# DA1469x register map
Vendor: Dialog; Series: DA1469x; File version: 1.2
CPU: CM33 r1p0, little endian, no MPU, FPU, 3 interrupt priority bits
Registers are 32-bit, read-write, reset 0x0 unless marked. A register's access mark holds for its fields unless they carry their own. Offsets are from the block's base; [hi:lo] are bit positions; 'fields as' and 'values as' point back to an identical list.

## CRG_COM — CRG_COM registers
Base 0x50020900
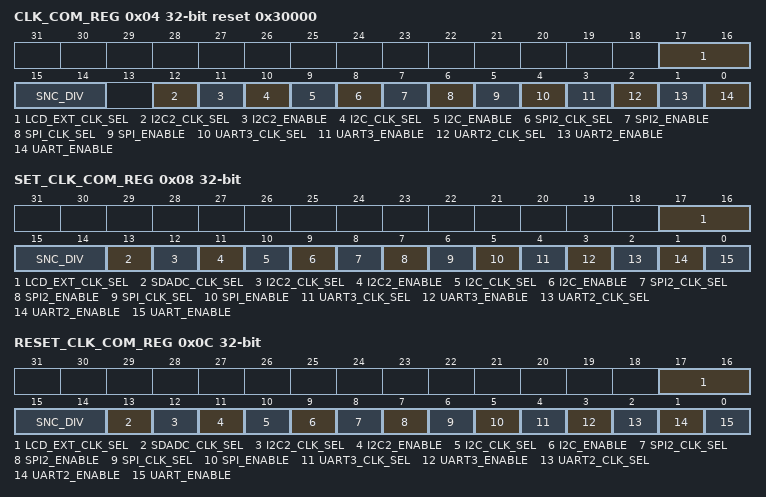
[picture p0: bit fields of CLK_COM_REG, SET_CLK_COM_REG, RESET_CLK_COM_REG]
0x04 CLK_COM_REG reset 0x30000 — Peripheral divider register
  [17:16] LCD_EXT_CLK_SEL — Select LCD external clock speed. 0x0: 1 Hz 0x1: 62.5 Hz 0x2: 125 Hz 0x3: off
  [15:14] SNC_DIV — Division factor for SNC, w.r.t. pclk setting 0x0 = divide by 1 0x1 = divide by 2 0x2 = divide by 4 0x3 = divide by 8
  [12] I2C2_CLK_SEL — Selects the clock source 1 = DIV1 clock 0 = DIVN clock
  [11] I2C2_ENABLE — Enables the clock
  [10] I2C_CLK_SEL — Selects the clock source 1 = DIV1 clock 0 = DIVN clock
  [9] I2C_ENABLE — Enables the clock
  [8] SPI2_CLK_SEL — Selects the clock source 1 = DIV1 clock 0 = DIVN clock
  [7] SPI2_ENABLE — Enables the clock
  [6] SPI_CLK_SEL — Selects the clock source 1 = DIV1 clock 0 = DIVN clock
  [5] SPI_ENABLE — Enables the clock
  [4] UART3_CLK_SEL — Selects the clock source 1 = DIV1 clock 0 = DIVN clock
  [3] UART3_ENABLE — Enables the clock
  [2] UART2_CLK_SEL — Selects the clock source 1 = DIV1 clock 0 = DIVN clock
  [1] UART2_ENABLE — Enables the clock
  [0] UART_ENABLE — Enables the clock
0x08 SET_CLK_COM_REG — Peripheral divider register SET register. Reads back 0x0000
  [17:16] LCD_EXT_CLK_SEL rw-once — Select LCD external clock speed. 0x0: 1 Hz 0x1: 62.5 Hz 0x2: 125 Hz 0x3: off
  [15:14] SNC_DIV rw-once — Division factor for SNC, w.r.t. pclk setting 0x0 = divide by 1 0x1 = divide by 2 0x2 = divide by 4 0x3 = divide by 8
  [13] SDADC_CLK_SEL rw-once — Selects the clock source 1 = DIV1 clock 0 = DIVN clock
  [12] I2C2_CLK_SEL rw-once — Selects the clock source 1 = DIV1 clock 0 = DIVN clock
  [11] I2C2_ENABLE rw-once — Enables the clock
  [10] I2C_CLK_SEL rw-once — Selects the clock source 1 = DIV1 clock 0 = DIVN clock
  [9] I2C_ENABLE rw-once — Enables the clock
  [8] SPI2_CLK_SEL rw-once — Selects the clock source 1 = DIV1 clock 0 = DIVN clock
  [7] SPI2_ENABLE rw-once — Enables the clock
  [6] SPI_CLK_SEL rw-once — Selects the clock source 1 = DIV1 clock 0 = DIVN clock
  [5] SPI_ENABLE rw-once — Enables the clock
  [4] UART3_CLK_SEL rw-once — Selects the clock source 1 = DIV1 clock 0 = DIVN clock
  [3] UART3_ENABLE rw-once — Enables the clock
  [2] UART2_CLK_SEL rw-once — Selects the clock source 1 = DIV1 clock 0 = DIVN clock
  [1] UART2_ENABLE rw-once — Enables the clock
  [0] UART_ENABLE rw-once — Enables the clock
0x0C RESET_CLK_COM_REG — Peripheral divider register RESET register. Reads back 0x0000
  [17:16] LCD_EXT_CLK_SEL — Select LCD external clock speed. 0x0: 1 Hz 0x1: 62.5 Hz 0x2: 125 Hz 0x3: off
  [15:14] SNC_DIV — Division factor for SNC, w.r.t. pclk setting 0x0 = divide by 1 0x1 = divide by 2 0x2 = divide by 4 0x3 = divide by 8
  [13] SDADC_CLK_SEL — Selects the clock source 1 = DIV1 clock 0 = DIVN clock
  [12] I2C2_CLK_SEL — Selects the clock source 1 = DIV1 clock 0 = DIVN clock
  [11] I2C2_ENABLE — Enables the clock
  [10] I2C_CLK_SEL — Selects the clock source 1 = DIV1 clock 0 = DIVN clock
  [9] I2C_ENABLE — Enables the clock
  [8] SPI2_CLK_SEL — Selects the clock source 1 = DIV1 clock 0 = DIVN clock
  [7] SPI2_ENABLE — Enables the clock
  [6] SPI_CLK_SEL — Selects the clock source 1 = DIV1 clock 0 = DIVN clock
  [5] SPI_ENABLE — Enables the clock
  [4] UART3_CLK_SEL — Selects the clock source 1 = DIV1 clock 0 = DIVN clock
  [3] UART3_ENABLE — Enables the clock
  [2] UART2_CLK_SEL — Selects the clock source 1 = DIV1 clock 0 = DIVN clock
  [1] UART2_ENABLE — Enables the clock
  [0] UART_ENABLE — Enables the clock

## CRG_PER — CRG_PER registers
Base 0x50030C00
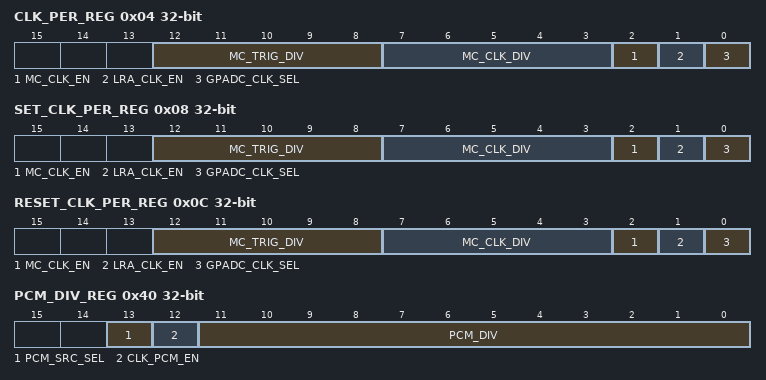
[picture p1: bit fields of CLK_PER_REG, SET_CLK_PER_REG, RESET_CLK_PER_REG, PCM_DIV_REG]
0x04 CLK_PER_REG — Peripheral divider register
  [12:8] MC_TRIG_DIV — Trigger divider for the motor controller 0x0: divide LP_CLK by 1 0x1: divide LP_CLK by 2 ... 0x1F: divide LP_CLK by 32
  [7:3] MC_CLK_DIV — Clock divider for the motor controller slot. The slots are clocked on (a PCLK synchronized version of) the LP clock, and can be further divided by this divider: 0x0: divide LP clock by 1 0x1: divide LP clock by 2 ... 0x1F: divide LP clock by 32
  [2] MC_CLK_EN — Enables the clock
  [1] LRA_CLK_EN — Enables the clock
  [0] GPADC_CLK_SEL — Selects the clock source 1 = DIV1 clock 0 = DIVN clock/ 2
0x08 SET_CLK_PER_REG — Peripheral divider register SET register, reads 0x0000
  [12:8] MC_TRIG_DIV rw-once — Trigger divider for the motor controller 0x0: divide LP_CLK by 1 0x1: divide LP_CLK by 2 ... 0x1F: divide LP_CLK by 32
  [7:3] MC_CLK_DIV rw-once — Clock divider for the motor controller slot. The slots are clocked on (a PCLK synchronized version of) the LP clock, and can be further divided by this divider: 0x0: divide LP clock by 1 0x1: divide LP clock by 2 ... 0x1F: divide LP clock by 32
  [2] MC_CLK_EN rw-once — Enables the clock
  [1] LRA_CLK_EN rw-once — Enables the clock
  [0] GPADC_CLK_SEL rw-once — Selects the clock source 1 = DIV1 clock 0 = DIVN clock/ 2
0x0C RESET_CLK_PER_REG — Peripheral divider register RESET register, reads 0x0000
  fields as CLK_PER_REG
0x40 PCM_DIV_REG — PCM divider and enables
  [13] PCM_SRC_SEL — Selects the clock source 1 = DIV1 clock 0 = DIVN clock
  [12] CLK_PCM_EN — Enable for the internally generated PCM clock The PCM_DIV must be set before or together with CLK_PCM_EN.
  [11:0] PCM_DIV — PCM clock divider. Minimum value is 0x2.
0x44 PCM_FDIV_REG — PCM fractional division register
  [15:0] PCM_FDIV — These bits define the fractional division part of the PCM clock. The left most '1' defines the denominator, the number of '1' bits define the numerator. E.g. 0x0110 means 2/9, with a distribution of 1.0001.0000 0xfeee means 13/16, with a distribution of 1111.1110.1110.1110
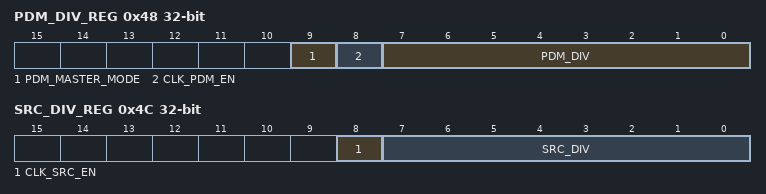
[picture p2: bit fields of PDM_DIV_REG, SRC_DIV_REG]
0x48 PDM_DIV_REG — PDM divider and enables
  [9] PDM_MASTER_MODE — Master mode selection 0: slave mode 1: master mode
  [8] CLK_PDM_EN — Enable for the internally generated PDM clock The PDM_DIV must be set before or together with CLK_PDM_EN.
  [7:0] PDM_DIV — PDM clock divider
0x4C SRC_DIV_REG — SRC divider and enables
  [8] CLK_SRC_EN — Enable for the internally generated SRC clock The SRC_DIV must be set before or together with CLK_SRC_EN.
  [7:0] SRC_DIV — SRC clock divider
